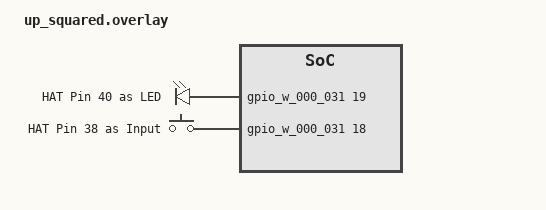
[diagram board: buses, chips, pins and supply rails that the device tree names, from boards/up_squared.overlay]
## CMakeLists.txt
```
# SPDX-License-Identifier: Apache-2.0

cmake_minimum_required(VERSION 3.13.1)
include($ENV{ZEPHYR_BASE}/cmake/app/boilerplate.cmake NO_POLICY_SCOPE)
project(gpio)

FILE(GLOB app_sources src/*.c)
target_sources(app PRIVATE ${app_sources})
```

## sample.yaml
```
sample:
  name: GPIO toggling
tests:
  sample.driver.gpio:
    tags: drivers
    filter: dt_compat_enabled_with_alias("gpio-leds", "led0") and
            dt_compat_enabled_with_alias("gpio-keys", "sw0")
    harness: console
    harness_config:
        type: one_line
        regex:
            - "Toggling (.*)"
    depends_on: gpio
```

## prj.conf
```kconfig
CONFIG_GPIO=y
CONFIG_SYS_TIMEOUT_LEGACY_API=y
```

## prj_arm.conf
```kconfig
CONFIG_STDOUT_CONSOLE=y
CONFIG_PRINTK=y
CONFIG_NANO_TIMERS=y
CONFIG_NANO_TIMEOUTS=y
CONFIG_GPIO=y
CONFIG_GPIO_ATMEL_SAM3=y
```

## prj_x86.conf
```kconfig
CONFIG_STDOUT_CONSOLE=y
CONFIG_PRINTK=y
CONFIG_GPIO=y
CONFIG_NANO_TIMERS=y
CONFIG_NANO_TIMEOUTS=y
```

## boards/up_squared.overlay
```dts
/*
 * Copyright (c) 2019 Intel Corporation
 *
 * SPDX-License-Identifier: Apache-2.0
 */

/*
 * This uses pin 40 on HAT as LED, and pin 38 as interrupt line.
 *
 * Note:
 * Need to change the BIOS settings:
 * () Advanced -> HAT Configurations:
 *    - HD-Audio / I2S6 Selec -> Disabled
 *
 *    - GPIO 27 (Pin38) Confi -> Input
 *    - GPIO 28 (Pin40) Confi -> Output
 */

/ {
	aliases {
		led0 = &led0;
		sw0 = &sw0;
	};

	leds {
		compatible = "gpio-leds";
		led0: led_0 {
			gpios = <&gpio_w_000_031 19 0>;
			label = "HAT Pin 40 as LED";
		};

	};

	buttons {
		compatible = "gpio-keys";
		sw0: switch_0 {
			gpios = <&gpio_w_000_031 18 0>;
			label = "HAT Pin 38 as Input";
		};
	};

};
```

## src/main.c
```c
/*
 * Copyright (c) 2015 Intel Corporation
 *
 * SPDX-License-Identifier: Apache-2.0
 */

/**
 * @file
 * @brief GPIO driver sample
 *
 * This sample toggles LED1 and waits for an interrupt on BUTTON1.
 * Note that an internal pull-up is set on BUTTON1 as the button
 * only drives low when pressed.
 */
#include <zephyr.h>

#include <sys/printk.h>

#include <device.h>
#include <drivers/gpio.h>
#include <sys/util.h>

#if defined(DT_ALIAS_SW0_GPIOS_CONTROLLER) && defined(DT_ALIAS_LED0_GPIOS_CONTROLLER)
#define GPIO_OUT_DRV_NAME DT_ALIAS_LED0_GPIOS_CONTROLLER
#define GPIO_OUT_PIN  DT_ALIAS_LED0_GPIOS_PIN
#define GPIO_IN_DRV_NAME DT_ALIAS_SW0_GPIOS_CONTROLLER
#define GPIO_INT_PIN  DT_ALIAS_SW0_GPIOS_PIN
#else
#error Change the pins based on your configuration. This sample \
	defaults to built-in buttons and LEDs
#endif

void gpio_callback(struct device *port,
		   struct gpio_callback *cb, u32_t pins)
{
	printk("Pin %s.%d triggered\n", port->config->name, pins);
}

static struct gpio_callback gpio_cb;

void main(void)
{
	struct device *gpio_out_dev, *gpio_in_dev;
	int ret;
	int toggle = 1;

	gpio_out_dev = device_get_binding(GPIO_OUT_DRV_NAME);
	if (!gpio_out_dev) {
		printk("Cannot find %s!\n", GPIO_OUT_DRV_NAME);
		return;
	}

	gpio_in_dev = device_get_binding(GPIO_IN_DRV_NAME);
	if (!gpio_in_dev) {
		printk("Cannot find %s!\n", GPIO_IN_DRV_NAME);
		return;
	}

	/* Setup GPIO output */
	ret = gpio_pin_configure(gpio_out_dev, GPIO_OUT_PIN, (GPIO_DIR_OUT));
	if (ret) {
		printk("Error configuring pin %s.%d!\n",
		       gpio_out_dev->config->name,
		       GPIO_OUT_PIN);
	}

	/* Setup GPIO input, and triggers on rising edge. */
#ifdef CONFIG_SOC_CC2650
	ret = gpio_pin_configure(gpio_in_dev, GPIO_INT_PIN,
				 (GPIO_DIR_IN | GPIO_INT |
				  GPIO_INT_EDGE | GPIO_INT_ACTIVE_HIGH |
				  GPIO_INT_DEBOUNCE | GPIO_PUD_PULL_UP));
#else
	ret = gpio_pin_configure(gpio_in_dev, GPIO_INT_PIN,
				 (GPIO_DIR_IN | GPIO_INT |
				  GPIO_INT_EDGE | GPIO_INT_ACTIVE_HIGH |
				  GPIO_INT_DEBOUNCE));
#endif
	if (ret) {
		printk("Error configuring pin %s.%d!\n",
		       gpio_in_dev->config->name,
		       GPIO_INT_PIN);
	}

	gpio_init_callback(&gpio_cb, gpio_callback, BIT(GPIO_INT_PIN));

	ret = gpio_add_callback(gpio_in_dev, &gpio_cb);
	if (ret) {
		printk("Cannot setup callback!\n");
	}

	ret = gpio_pin_enable_callback(gpio_in_dev, GPIO_INT_PIN);
	if (ret) {
		printk("Error enabling callback!\n");
	}

	while (1) {
		printk("Toggling pin %s.%d\n",
		       gpio_out_dev->config->name,
		       GPIO_OUT_PIN);

		ret = gpio_pin_write(gpio_out_dev, GPIO_OUT_PIN, toggle);
		if (ret) {
			printk("Error set pin %s.%d!\n",
			       gpio_out_dev->config->name,
			       GPIO_OUT_PIN);
		}

		if (toggle) {
			toggle = 0;
		} else {
			toggle = 1;
		}

		k_sleep(K_SECONDS(2));
	}
}
```
